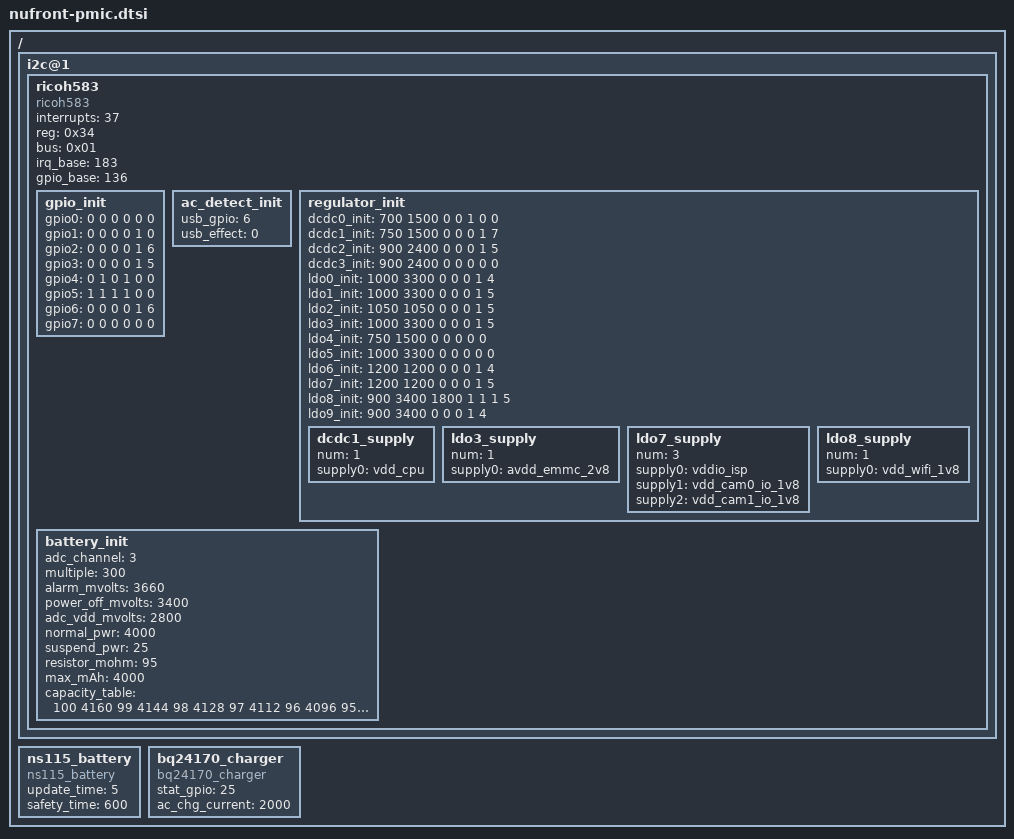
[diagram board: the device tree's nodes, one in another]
/{
	i2c@1 {
		ricoh583 {
			compatible = "ricoh583";
			interrupts = <37>;
			reg = <0x34>;
			bus = <0x01>;
			irq_base = <183>;
			gpio_base = <136>;
			gpio_init {
				gpio0 = <0 0 0 0 0 0>;
				gpio1 = <0 0 0 0 1 0>;
				gpio2 = <0 0 0 0 1 6>;
				gpio3 = <0 0 0 0 1 5>;
				gpio4 = <0 1 0 1 0 0>;
				gpio5 = <1 1 1 1 0 0>;
				gpio6 = <0 0 0 0 1 6>;
				gpio7 = <0 0 0 0 0 0>;
			};
			ac_detect_init {
				usb_gpio = <6>;
				usb_effect = <0>;
			};
			regulator_init {
				dcdc0_init = <700 1500 0 0 1 0 0>;
				dcdc1_init = <750 1500 0 0 0 1 7>;
				dcdc2_init = <900 2400 0 0 0 1 5>;
				dcdc3_init = <900 2400 0 0 0 0 0>;
				ldo0_init  = <1000 3300 0 0 0 1 4>;
				ldo1_init = <1000 3300 0 0 0 1 5>;
				ldo2_init = <1050 1050 0 0 0 1 5>;
				ldo3_init = <1000 3300 0 0 0 1 5>;
				ldo4_init = <750 1500 0 0 0 0 0>;
				ldo5_init = <1000 3300 0 0 0 0 0>;
				ldo6_init = <1200 1200 0 0 0 1 4>;
				ldo7_init  = <1200 1200 0 0 0 1 5>;
				ldo8_init = <900 3400 1800 1 1 1 5>;
				ldo9_init = <900 3400 0 0 0 1 4>;
				dcdc1_supply {
					num = <1>;
					supply0 = "vdd_cpu";
				};
				ldo3_supply {
					num = <1>;
					supply0 = "avdd_emmc_2v8";
				};
				ldo7_supply {
					num = <3>;
					supply0 = "vddio_isp";
					supply1 = "vdd_cam0_io_1v8";
					supply2 = "vdd_cam1_io_1v8";
				};
				ldo8_supply {
					num = <1>;
					supply0 = "vdd_wifi_1v8";
				};
			};
			battery_init {
				adc_channel = <3>;
				multiple = <300>;
				alarm_mvolts = <3660>;
				power_off_mvolts = <3400>;
				adc_vdd_mvolts = <2800>;
				normal_pwr = <4000>;
				suspend_pwr = <25>;
				resistor_mohm = <95>;
				max_mAh = <4000>;
				capacity_table = <100 4160 99 4144 98 4128 97 4112 96 4096 95 4080 94 4064 93 4048 92 4032 91 4016 90 4000 89 3996 88 3992 87 3988 86 3984 85 3980 84 3976 83 3972 82 3968 81 3964 80 3962 79 3959 78 3956 77 3954 76 3952 75 3950 74 3948 73 3946 72 3944 71 3942 70 3940 79 3936 68 3932 67 3928 66 3924 65 3920 64 3916 63 3912 62 3908 61 3904 60 3900 59 3894 58 3888 57 3882 56 3876 55 3870 54 3864 53 3858 52 3852 51 3846 50 3840 49 3835 48 3830 47 3825 46 3820 45 3815 44 3810 43 3805 42 3800 41 3795 40 3790 39 3783 38 3776 37 3769 36 3762 35 3755 34 3748 33 3741 32 3734 31 3727 30 3720 29 3716 28 3712 27 3708 26 3704 25 3700 24 3696 23 3692 22 3688 21 3684 20 3680 19 3676 18 3672 17 3668 16 3664 15 3660 14 3656 13 3652 12 3648 11 3644 10 3640 9 3636 8 3632 7 3628 6 3624 5 3620 4 3616 3 3612 2 3608 1 3604 0 3600>;
			};
		};
	};


	ns115_battery {
		compatible = "ns115_battery";
		update_time = <5>;
		safety_time = <600>;
	};
	bq24170_charger {
		compatible = "bq24170_charger";
		stat_gpio = <25>;
		ac_chg_current = <2000>;
	};
};
